# C7X256V_CLEC_CLEC_EVT_7C200000h register map
Vendor: Texas Instruments
Peripheral module from a debugger description file (folder am62D).
Registers are 32-bit, read-only, reset values left out (the file's numbers can be read two ways) unless marked. A register's access mark holds for its fields unless they carry their own. Offsets are as the file gives them; lines under a group give offsets from that group; [hi:lo] are bit positions; {n}, {i} and the like mark numbered series; 'fields as' and 'values as' point back to an identical list; <NAME> marks a mode.

## clec_evt
0x00 clec_evt_GLOBAL access not given
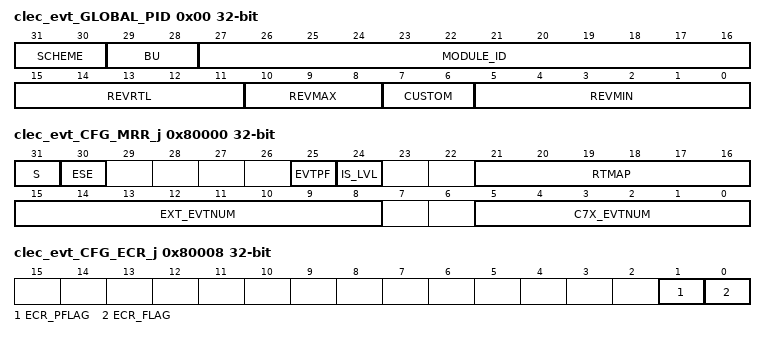
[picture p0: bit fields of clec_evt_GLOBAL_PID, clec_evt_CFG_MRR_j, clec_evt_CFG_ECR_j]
0x00 clec_evt_GLOBAL_PID — Revision parameters
  [31:30] SCHEME — Scheme Reset Source: mod_g_rst_n
  [29:28] BU — Scheme Reset Source: mod_g_rst_n
  [27:16] MODULE_ID — Module ID Reset Source: mod_g_rst_n
  [15:11] REVRTL — RTL version Reset Source: mod_g_rst_n
  [10:8] REVMAX — Major version Reset Source: mod_g_rst_n
  [7:6] CUSTOM — Custom version Reset Source: mod_g_rst_n
  [5:0] REVMIN — Minor version Reset Source: mod_g_rst_n
0xA000 clec_evt_GLOBAL_SET_FLAG_EFR_k — CLEC event flags
  [31:0] EVNTFR — event flag register, read only pending status of all events regardless of they are enabled or disabled, for pulse events this flag is cleared as soon as event is sent, for level events this flag is cleared when input event is deasserted, writing 1 to ECR_n register also clears this bit in case of pending pulse event, description in spec section 4.2.2 Reset Source: mod_g_rst_n
0xB000 clec_evt_GLOBAL_DROP_FLAG_EDR_k — CLEC dropped event flags
  [31:0] EVNTDR — dropped event flags, for input events which are pulse if events are sent back back and second event gets dropped since first event still in the pending event queue, this bit gets set indicating that an event has been dropped, it also generates dropped event interrupt, description in spec section 4.2.3 Reset Source: mod_g_rst_n
0xC000 clec_evt_GLOBAL_GELRS rw — Event Lock reg for secure claim
  [0] LOCK — GELRS.LOCK - event lock register for secure claim Reset Source: mod_g_rst_n
0xD000 clec_evt_GLOBAL_GELRNS rw — Event Lock reg for non-secure claim
  [0] LOCK — GELRNS.LOCK - event lock register for non-secure claim Reset Source: mod_g_rst_n
0x80000 clec_evt_CFG_MRR_j access per field — Map and routing register
  [31] S rw — MRR.S - reserved, not used for AM62A since CPU doesn't support secure mode Reset Source: mod_g_rst_n
  [30] ESE rw — MRR.ESE - Event-Send enable. Controls whether CLEC sends this eventwhen ESR is written or Event occurred on interrupt line Reset Source: mod_g_rst_n
  [25] EVTPF ro — MRR.EPF - same value as EFR, read only pending status of all events regardless of they are enabled or disabled, for pulse events this flag is cleared as soon as event is sent, for level events this flag is cleared when input event is deasserted, writing 1 to ECR_n register also clears this bit in case of pending pulse event Reset Source: mod_g_rst_n
  [24] IS_LVL rw — MRR.IS_LVL - Indicate that input event is level or pulse, event handling is different based on whether event is level or pulse Reset Source: mod_g_rst_n
  [21:16] RTMAP rw — MRR.RTMAP - If Bit [16] = 1 Send to None, If Bit [17] = 1 and bit [16] = 0 Send to System, If [16] = 0 and [17] = 0 send to [21:18] Corepac encoded value - value 1 and 0xF are valid since there is only one CPU Reset Source: mod_g_rst_n
  [15:8] EXT_EVTNUM rw — MRR.EXT_EVTNUM - encoded external event number, event 0- 63 SOC events, 64-95 DRU events, event 128 ARM event others are reserved for AM62A Reset Source: mod_g_rst_n
  [5:0] C7X_EVTNUM rw — MRR.C7x_EVTNUM - C7x event number to send when this event is triggered Reset Source: mod_g_rst_n
0x80004 clec_evt_CFG_ESR_j wo — Event send reg
  [31:0] ESR_N — ESR.ESR_n sends event number n if it is enabled, address offset 0x010000 * n + 0x03000 Reset Source: mod_g_rst_n
0x80008 clec_evt_CFG_ECR_j wo — Event clear reg
  [1] ECR_PFLAG — ECR.EDR_Clear - clears EDR flag bit when 2 is written Reset Source: mod_g_rst_n
  [0] ECR_FLAG — ECR.EFR_Clear - clears EFR flag bit when 1 is written, also clears corresponding SOC level event if sent to system on SOCinterrupt port Reset Source: mod_g_rst_n
